# RockChip_RK3588 register map
Vendor: RockChip Electronics Co., Ltd.; Series: RK3588; File version: 0.1
Registers are 32-bit, read-write, no defined reset value unless marked. A register's access mark holds for its fields unless they carry their own. Offsets are from the block's base; [hi:lo] are bit positions; {n}, {i} and the like mark numbered series.

## IOC_VCCIO3_5
Base 0xFD5FA000
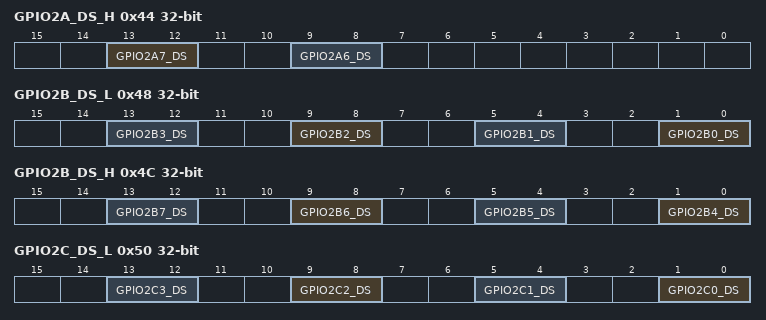
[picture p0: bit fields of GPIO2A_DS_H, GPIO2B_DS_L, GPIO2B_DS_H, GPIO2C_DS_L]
0x44 GPIO2A_DS_H — GPIO2A Driver Strength Control High bits
  [13:12] GPIO2A7_DS — GPIO2A7 DS control Driver Strength Selection
    0=2_5MA_100OHM; 2=5MA_50OHM; 1=7_5MA_33OHM; 3=10MA_25OHM
  [9:8] GPIO2A6_DS — GPIO2A6 DS control Driver Strength Selection
    0=2_5MA_100OHM; 2=5MA_50OHM; 1=7_5MA_33OHM; 3=10MA_25OHM
0x48 GPIO2B_DS_L — GPIO2B Driver Strength Control Low bits
  [all] fields
    0=2_5MA_100OHM; 2=5MA_50OHM; 1=7_5MA_33OHM; 3=10MA_25OHM
  [4n+1:4n] GPIO2B{n}_DS (n=0..3) — GPIO2B{n} DS control Driver Strength Selection
0x4C GPIO2B_DS_H — GPIO2B Driver Strength Control High bits
  [all] fields
    0=2_5MA_100OHM; 2=5MA_50OHM; 1=7_5MA_33OHM; 3=10MA_25OHM
  [4n-15:4n-16] GPIO2B{n}_DS (n=4..7) — GPIO2B{n} DS control Driver Strength Selection
0x50 GPIO2C_DS_L — GPIO2C Driver Strength Control Low bits
  [all] fields
    0=2_5MA_100OHM; 2=5MA_50OHM; 1=7_5MA_33OHM; 3=10MA_25OHM
  [4n+1:4n] GPIO2C{n}_DS (n=0..3) — GPIO2C{n} DS control Driver Strength Selection
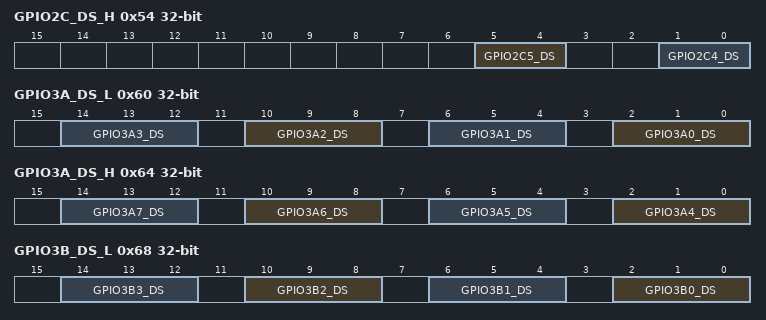
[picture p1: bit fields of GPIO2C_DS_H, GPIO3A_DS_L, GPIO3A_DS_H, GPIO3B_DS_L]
0x54 GPIO2C_DS_H — GPIO2C Driver Strength Control High bits
  [5:4] GPIO2C5_DS — GPIO2C5 DS control Driver Strength Selection
    0=2_5MA_100OHM; 2=5MA_50OHM; 1=7_5MA_33OHM; 3=10MA_25OHM
  [1:0] GPIO2C4_DS — GPIO2C4 DS control Driver Strength Selection
    0=2_5MA_100OHM; 2=5MA_50OHM; 1=7_5MA_33OHM; 3=10MA_25OHM
0x60 GPIO3A_DS_L — GPIO3A Driver Strength Control Low bits
  [all] fields
    0=100OHM; 4=66OHM; 2=50OHM; 6=40OHM; 1=33OHM; 5=25OHM
  [4n+2:4n] GPIO3A{n}_DS (n=0..3) — GPIO3A{n} DS control Driver Strength Selection
0x64 GPIO3A_DS_H — GPIO3A Driver Strength Control High bits
  [all] fields
    0=100OHM; 4=66OHM; 2=50OHM; 6=40OHM; 1=33OHM; 5=25OHM
  [4n-14:4n-16] GPIO3A{n}_DS (n=4..7) — GPIO3A{n} DS control Driver Strength Selection
0x68 GPIO3B_DS_L — GPIO3B Driver Strength Control Low bits
  [all] fields
    0=100OHM; 4=66OHM; 2=50OHM; 6=40OHM; 1=33OHM; 5=25OHM
  [4n+2:4n] GPIO3B{n}_DS (n=0..3) — GPIO3B{n} DS control Driver Strength Selection
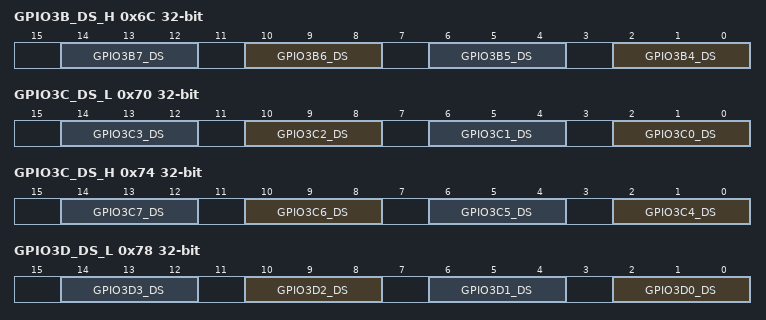
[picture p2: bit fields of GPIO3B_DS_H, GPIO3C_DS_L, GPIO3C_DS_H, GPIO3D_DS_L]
0x6C GPIO3B_DS_H — GPIO3B Driver Strength Control High bits
  [all] fields
    0=100OHM; 4=66OHM; 2=50OHM; 6=40OHM; 1=33OHM; 5=25OHM
  [4n-14:4n-16] GPIO3B{n}_DS (n=4..7) — GPIO3B{n} DS control Driver Strength Selection
0x70 GPIO3C_DS_L — GPIO3C Driver Strength Control Low bits
  [all] fields
    0=100OHM; 4=66OHM; 2=50OHM; 6=40OHM; 1=33OHM; 5=25OHM
  [4n+2:4n] GPIO3C{n}_DS (n=0..3) — GPIO3C{n} DS control Driver Strength Selection
0x74 GPIO3C_DS_H — GPIO3C Driver Strength Control High bits
  [all] fields
    0=100OHM; 4=66OHM; 2=50OHM; 6=40OHM; 1=33OHM; 5=25OHM
  [4n-14:4n-16] GPIO3C{n}_DS (n=4..7) — GPIO3C{n} DS control Driver Strength Selection
0x78 GPIO3D_DS_L — GPIO3D Driver Strength Control Low bits
  [all] fields
    0=100OHM; 4=66OHM; 2=50OHM; 6=40OHM; 1=33OHM; 5=25OHM
  [4n+2:4n] GPIO3D{n}_DS (n=0..3) — GPIO3D{n} DS control Driver Strength Selection
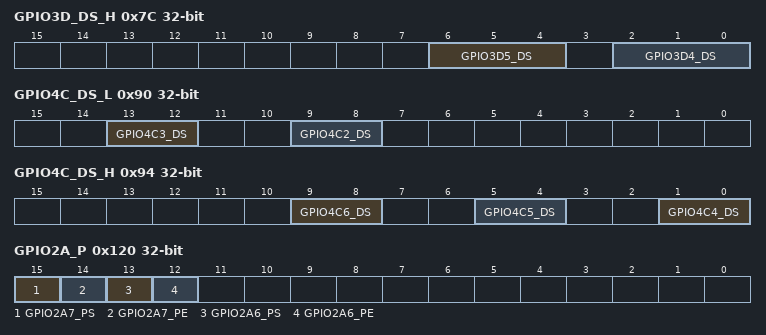
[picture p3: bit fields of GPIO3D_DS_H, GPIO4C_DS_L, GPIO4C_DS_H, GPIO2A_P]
0x7C GPIO3D_DS_H — GPIO3D Driver Strength Control High bits
  [6:4] GPIO3D5_DS — GPIO3D5 DS control Driver Strength Selection
    0=100OHM; 4=66OHM; 2=50OHM; 6=40OHM; 1=33OHM; 5=25OHM
  [2:0] GPIO3D4_DS — GPIO3D4 DS control Driver Strength Selection
    0=100OHM; 4=66OHM; 2=50OHM; 6=40OHM; 1=33OHM; 5=25OHM
0x90 GPIO4C_DS_L — GPIO4C Driver Strength Control Low bits
  [13:12] GPIO4C3_DS — GPIO4C3 DS control Driver Strength Selection
    0=2_5MA_100OHM; 2=5MA_50OHM; 1=7_5MA_33OHM; 3=10MA_25OHM
  [9:8] GPIO4C2_DS — GPIO4C2 DS control Driver Strength Selection
    0=2_5MA_100OHM; 2=5MA_50OHM; 1=7_5MA_33OHM; 3=10MA_25OHM
0x94 GPIO4C_DS_H — GPIO4C Driver Strength Control High bits
  [all] fields
    0=2_5MA_100OHM; 2=5MA_50OHM; 1=7_5MA_33OHM; 3=10MA_25OHM
  [9:8] GPIO4C6_DS — GPIO4C6 DS control Driver Strength Selection
  [5:4] GPIO4C5_DS — GPIO4C5 DS control Driver Strength Selection
  [1:0] GPIO4C4_DS — GPIO4C4 DS control Driver Strength Selection
0x120 GPIO2A_P — GPIO2A Pull-up/down Control
  [15] GPIO2A7_PS — GPIO2A7 PS control Weak PU/PD Resistor Selection
    0=PD_SELECTION; 1=PU_SELECTION
  [14] GPIO2A7_PE — GPIO2A7 PE control Active High Weak PU/PD Resistor Enable
    0=PU_PD_DISABLE; 1=PU_PD_ENABLE
  [13] GPIO2A6_PS — GPIO2A6 PS control Weak PU/PD Resistor Selection
    0=PD_SELECTION; 1=PU_SELECTION
  [12] GPIO2A6_PE — GPIO2A6 PE control Active High Weak PU/PD Resistor Enable
    0=PU_PD_DISABLE; 1=PU_PD_ENABLE
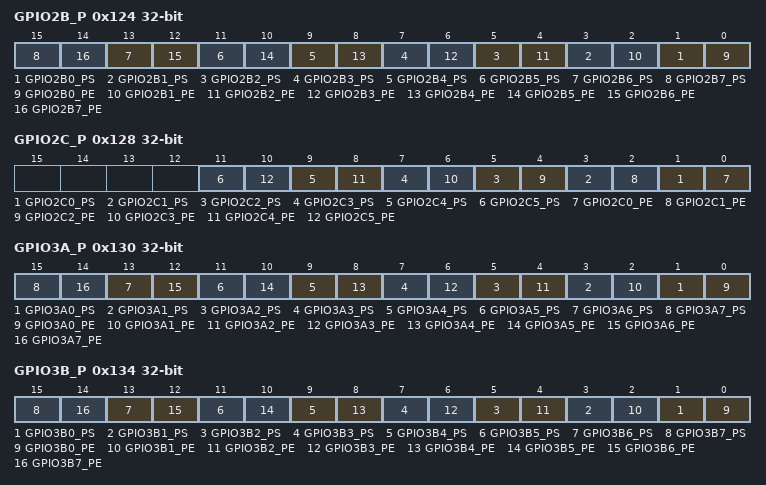
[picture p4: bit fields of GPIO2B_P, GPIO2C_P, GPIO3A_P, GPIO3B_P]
0x124 GPIO2B_P — GPIO2B Pull-up/down Control
  [2n+1] GPIO2B{n}_PS (n=0..7) — GPIO2B{n} PS control Weak PU/PD Resistor Selection
    0=PD_SELECTION; 1=PU_SELECTION
  [2n] GPIO2B{n}_PE (n=0..7) — GPIO2B{n} PE control Active High Weak PU/PD Resistor Enable
    0=PU_PD_DISABLE; 1=PU_PD_ENABLE
0x128 GPIO2C_P — GPIO2C Pull-up/down Control
  [2n+1] GPIO2C{n}_PS (n=0..5) — GPIO2C{n} PS control Weak PU/PD Resistor Selection
    0=PD_SELECTION; 1=PU_SELECTION
  [2n] GPIO2C{n}_PE (n=0..5) — GPIO2C{n} PE control Active High Weak PU/PD Resistor Enable
    0=PU_PD_DISABLE; 1=PU_PD_ENABLE
0x130 GPIO3A_P — GPIO3A Pull-up/down Control
  [2n+1] GPIO3A{n}_PS (n=0..7) — GPIO3A{n} PS control Weak PU/PD Resistor Selection
    0=PD_SELECTION; 1=PU_SELECTION
  [2n] GPIO3A{n}_PE (n=0..7) — GPIO3A{n} PE control Active High Weak PU/PD Resistor Enable
    0=PU_PD_DISABLE; 1=PU_PD_ENABLE
0x134 GPIO3B_P — GPIO3B Pull-up/down Control
  [2n+1] GPIO3B{n}_PS (n=0..7) — GPIO3B{n} PS control Weak PU/PD Resistor Selection
    0=PD_SELECTION; 1=PU_SELECTION
  [2n] GPIO3B{n}_PE (n=0..7) — GPIO3B{n} PE control Active High Weak PU/PD Resistor Enable
    0=PU_PD_DISABLE; 1=PU_PD_ENABLE
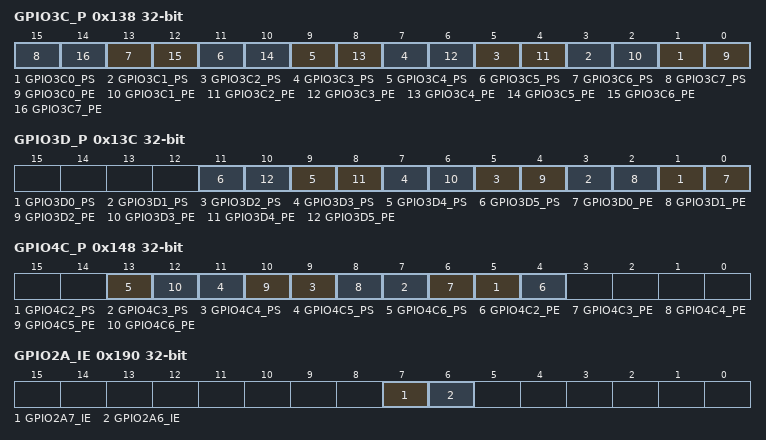
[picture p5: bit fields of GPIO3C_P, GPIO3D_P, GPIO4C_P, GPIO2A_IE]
0x138 GPIO3C_P — GPIO3C Pull-up/down Control
  [2n+1] GPIO3C{n}_PS (n=0..7) — GPIO3C{n} PS control Weak PU/PD Resistor Selection
    0=PD_SELECTION; 1=PU_SELECTION
  [2n] GPIO3C{n}_PE (n=0..7) — GPIO3C{n} PE control Active High Weak PU/PD Resistor Enable
    0=PU_PD_DISABLE; 1=PU_PD_ENABLE
0x13C GPIO3D_P — GPIO3D Pull-up/down Control
  [2n+1] GPIO3D{n}_PS (n=0..5) — GPIO3D{n} PS control Weak PU/PD Resistor Selection
    0=PD_SELECTION; 1=PU_SELECTION
  [2n] GPIO3D{n}_PE (n=0..5) — GPIO3D{n} PE control Active High Weak PU/PD Resistor Enable
    0=PU_PD_DISABLE; 1=PU_PD_ENABLE
0x148 GPIO4C_P — GPIO4C Pull-up/down Control
  [2n+1] GPIO4C{n}_PS (n=2..6) — GPIO4C{n} PS control Weak PU/PD Resistor Selection
    0=PD_SELECTION; 1=PU_SELECTION
  [2n] GPIO4C{n}_PE (n=2..6) — GPIO4C{n} PE control Active High Weak PU/PD Resistor Enable
    0=PU_PD_DISABLE; 1=PU_PD_ENABLE
0x190 GPIO2A_IE — GPIO2A Input Enable Control
  [7] GPIO2A7_IE — GPIO2A7 IE control Active High input buffer enable
    1=ENABLE; 0=DISABLE
  [6] GPIO2A6_IE — GPIO2A6 IE control Active High input buffer enable
    1=ENABLE; 0=DISABLE
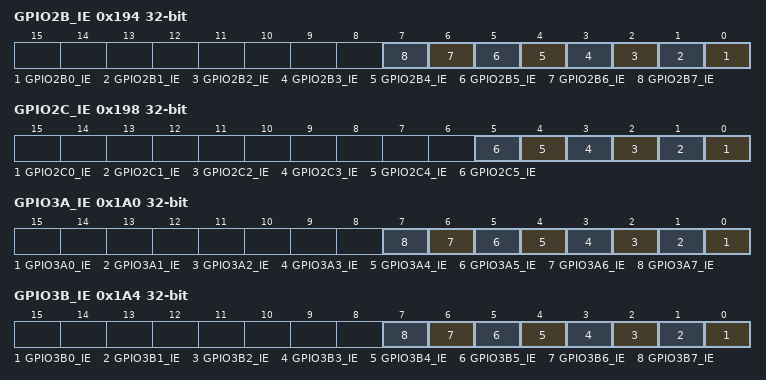
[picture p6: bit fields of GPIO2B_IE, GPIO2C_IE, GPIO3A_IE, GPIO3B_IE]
0x194 GPIO2B_IE — GPIO2B Input Enable Control
  [all] fields
    1=ENABLE; 0=DISABLE
  [n] GPIO2B{n}_IE (n=0..7) — GPIO2B{n} IE control Active High input buffer enable
0x198 GPIO2C_IE — GPIO2C Input Enable Control
  [all] fields
    1=ENABLE; 0=DISABLE
  [n] GPIO2C{n}_IE (n=0..5) — GPIO2C{n} IE control Active High input buffer enable
0x1A0 GPIO3A_IE — GPIO3A Input Enable Control
  [all] fields
    1=ENABLE; 0=DISABLE
  [n] GPIO3A{n}_IE (n=0..7) — GPIO3A{n} IE control Active High input buffer enable
0x1A4 GPIO3B_IE — GPIO3B Input Enable Control
  [all] fields
    1=ENABLE; 0=DISABLE
  [n] GPIO3B{n}_IE (n=0..7) — GPIO3B{n} IE control Active High input buffer enable
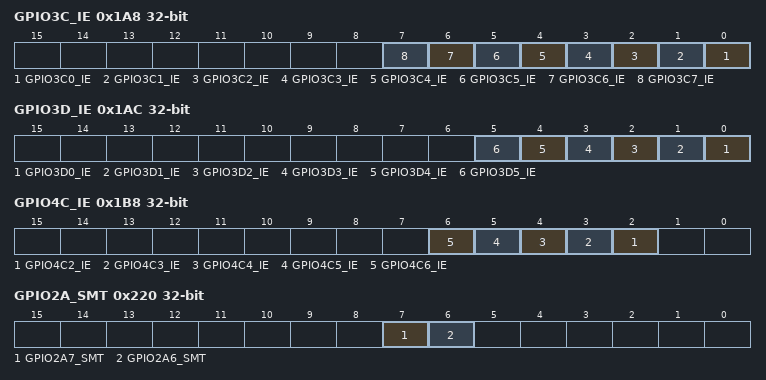
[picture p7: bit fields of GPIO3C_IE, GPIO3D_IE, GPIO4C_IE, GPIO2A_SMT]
0x1A8 GPIO3C_IE — GPIO3C Input Enable Control
  [all] fields
    1=ENABLE; 0=DISABLE
  [n] GPIO3C{n}_IE (n=0..7) — GPIO3C{n} IE control Active High input buffer enable
0x1AC GPIO3D_IE — GPIO3D Input Enable Control
  [all] fields
    1=ENABLE; 0=DISABLE
  [n] GPIO3D{n}_IE (n=0..5) — GPIO3D{n} IE control Active High input buffer enable
0x1B8 GPIO4C_IE — GPIO4C Input Enable Control
  [all] fields
    1=ENABLE; 0=DISABLE
  [n] GPIO4C{n}_IE (n=2..6) — GPIO4C{n} IE control Active High input buffer enable
0x220 GPIO2A_SMT — GPIO2A Schmitt Trigger Control
  [7] GPIO2A7_SMT — GPIO2A7 SMT control CMOS/Schmitt Trigger Selection
    0=CMOS; 1=SCHMITT_TRIGGER
  [6] GPIO2A6_SMT — GPIO2A6 SMT control CMOS/Schmitt Trigger Selection
    0=CMOS; 1=SCHMITT_TRIGGER
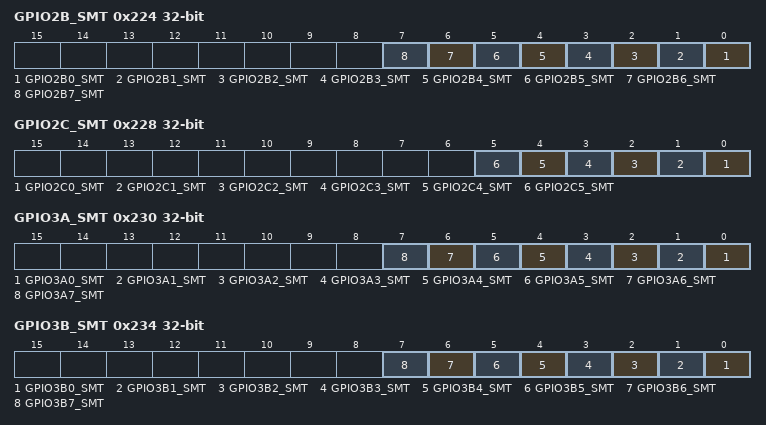
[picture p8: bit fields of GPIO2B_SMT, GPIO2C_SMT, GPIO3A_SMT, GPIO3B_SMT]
0x224 GPIO2B_SMT — GPIO2B Schmitt Trigger Control
  [all] fields
    0=CMOS; 1=SCHMITT_TRIGGER
  [n] GPIO2B{n}_SMT (n=0..7) — GPIO2B{n} SMT control CMOS/Schmitt Trigger Selection
0x228 GPIO2C_SMT — GPIO2C Schmitt Trigger Control
  [all] fields
    0=CMOS; 1=SCHMITT_TRIGGER
  [n] GPIO2C{n}_SMT (n=0..5) — GPIO2C{n} SMT control CMOS/Schmitt Trigger Selection
0x230 GPIO3A_SMT — GPIO3A Schmitt Trigger Control
  [all] fields
    0=CMOS; 1=SCHMITT_TRIGGER
  [n] GPIO3A{n}_SMT (n=0..7) — GPIO3A{n} SMT control CMOS/Schmitt Trigger Selection
0x234 GPIO3B_SMT — GPIO3B Schmitt Trigger Control
  [all] fields
    0=CMOS; 1=SCHMITT_TRIGGER
  [n] GPIO3B{n}_SMT (n=0..7) — GPIO3B{n} SMT control CMOS/Schmitt Trigger Selection
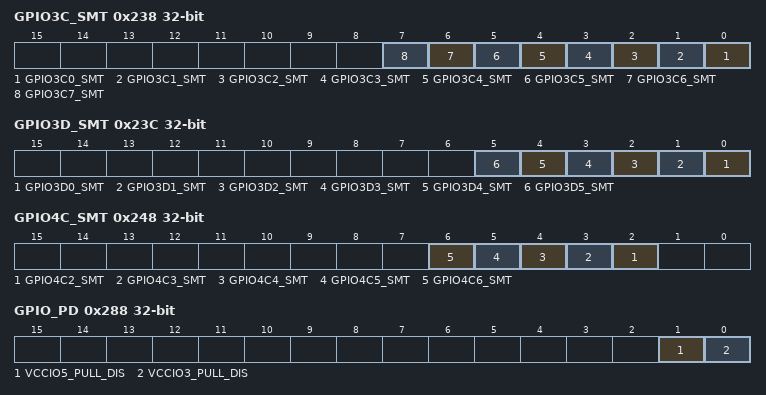
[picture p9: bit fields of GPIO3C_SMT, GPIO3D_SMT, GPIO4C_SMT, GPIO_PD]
0x238 GPIO3C_SMT — GPIO3C Schmitt Trigger Control
  [all] fields
    0=CMOS; 1=SCHMITT_TRIGGER
  [n] GPIO3C{n}_SMT (n=0..7) — GPIO3C{n} SMT control CMOS/Schmitt Trigger Selection
0x23C GPIO3D_SMT — GPIO3D Schmitt Trigger Control
  [all] fields
    0=CMOS; 1=SCHMITT_TRIGGER
  [n] GPIO3D{n}_SMT (n=0..5) — GPIO3D{n} SMT control CMOS/Schmitt Trigger Selection
0x248 GPIO4C_SMT — GPIO4C Schmitt Trigger Control
  [all] fields
    0=CMOS; 1=SCHMITT_TRIGGER
  [n] GPIO4C{n}_SMT (n=2..6) — GPIO4C{n} SMT control CMOS/Schmitt Trigger Selection
0x288 GPIO_PD IS — Auto Pull-up/down disable Control
  [1] VCCIO5_PULL_DIS
    1=DISABLE (disable VCCIO5 GPIO pull up/down when output enable)
  [0] VCCIO3_PULL_DIS
    1=DISABLE (disable VCCIO3 GPIO pull up/down when output enable)
